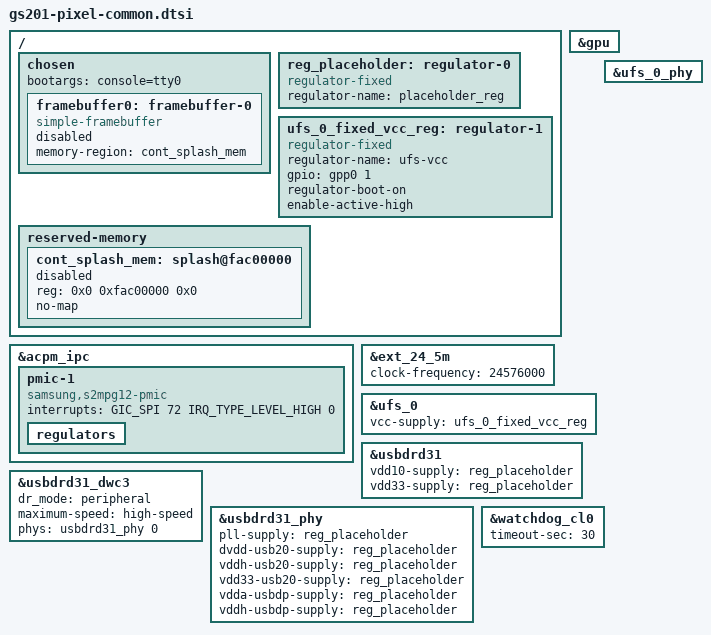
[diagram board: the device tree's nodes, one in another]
// SPDX-License-Identifier: GPL-2.0-only
/*
 * Device Tree nodes common for all GS201-based Pixel
 *
 * Copyright 2021-2023 Google LLC
 * Copyright 2023 Linaro Ltd - <peter.griffin@linaro.org>
 */

/dts-v1/;

#include <dt-bindings/gpio/gpio.h>
#include "gs201.dtsi"

/ {
	chosen {
		/*
		 * Bootloader expects bootargs specified otherwise it crashes.
		 * It also drops console= from the boot image command lines and
		 * appends console=null, so the console has to be set here.
		 */
		bootargs = "console=tty0";

		/* Use display framebuffer as setup by bootloader */
		framebuffer0: framebuffer-0 {
			compatible = "simple-framebuffer";
			memory-region = <&cont_splash_mem>;
			/* format properties to be added by actual board */

			status = "disabled";
		};
	};

	/* TODO: Replace with the S2MPG12 and S2MPG13 rails */
	reg_placeholder: regulator-0 {
		compatible = "regulator-fixed";
		regulator-name = "placeholder_reg";
	};

	/* TODO: Remove this once S2MPG13 slave PMIC is implemented */
	ufs_0_fixed_vcc_reg: regulator-1 {
		compatible = "regulator-fixed";
		regulator-name = "ufs-vcc";
		gpio = <&gpp0 1 GPIO_ACTIVE_HIGH>;
		regulator-boot-on;
		enable-active-high;
	};

	reserved-memory {
		cont_splash_mem: splash@fac00000 {
			/* size to be updated by actual board */
			reg = <0x0 0xfac00000 0x0>;
			no-map;

			status = "disabled";
		};
	};
};

&acpm_ipc {
	pmic-1 {
		compatible = "samsung,s2mpg12-pmic";
		interrupts = <GIC_SPI 72 IRQ_TYPE_LEVEL_HIGH 0>;

		regulators {
		};
	};
};

&ext_24_5m {
	clock-frequency = <24576000>;
};

&gpu {
	status = "okay";
};

&ufs_0 {
	vcc-supply = <&ufs_0_fixed_vcc_reg>;

	status = "okay";
};

&ufs_0_phy {
	status = "okay";
};

&usbdrd31 {
	vdd10-supply = <&reg_placeholder>;
	vdd33-supply = <&reg_placeholder>;

	status = "okay";
};

/*
 * Without a Type-C port controller the PHY forces VBUS valid, so run as a
 * USB 2.0 peripheral. Boards that describe theirs switch to OTG.
 */
&usbdrd31_dwc3 {
	dr_mode = "peripheral";
	maximum-speed = "high-speed";
	phys = <&usbdrd31_phy 0>;
	phy-names = "usb2-phy";

	status = "okay";
};

&usbdrd31_phy {
	/* TODO: Update these once PMIC is implemented */
	pll-supply = <&reg_placeholder>;
	dvdd-usb20-supply = <&reg_placeholder>;
	vddh-usb20-supply = <&reg_placeholder>;
	vdd33-usb20-supply = <&reg_placeholder>;
	vdda-usbdp-supply = <&reg_placeholder>;
	vddh-usbdp-supply = <&reg_placeholder>;

	status = "okay";
};

&watchdog_cl0 {
	timeout-sec = <30>;

	status = "okay";
};
